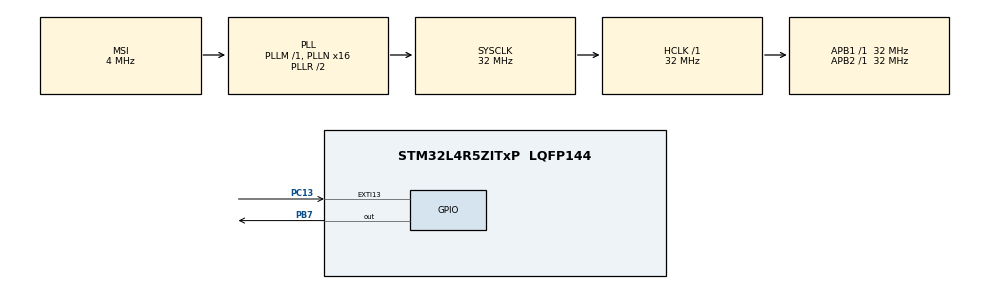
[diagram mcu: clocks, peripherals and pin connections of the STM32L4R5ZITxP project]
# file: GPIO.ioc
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Mcu.Family=STM32L4
Mcu.Name=STM32L4R5ZITxP
Mcu.Package=LQFP144
NVIC.EXTI15_10_IRQn=true\:0\:0\:false\:false\:true\:true\:true\:true
NVIC.PriorityGroup=NVIC_PRIORITYGROUP_4
PB7.Signal=GPIO_Output
PC13.Signal=GPXTI13
PC14-OSC32_IN\ (PC14).Mode=LSE-External-Oscillator
PC14-OSC32_IN\ (PC14).Signal=RCC_OSC32_IN
PC15-OSC32_OUT\ (PC15).Mode=LSE-External-Oscillator
PC15-OSC32_OUT\ (PC15).Signal=RCC_OSC32_OUT
PH0-OSC_IN\ (PH0).Mode=HSE-External-Oscillator
PH0-OSC_IN\ (PH0).Signal=RCC_OSC_IN
PH1-OSC_OUT\ (PH1).Mode=HSE-External-Oscillator
PH1-OSC_OUT\ (PH1).Signal=RCC_OSC_OUT
ProjectManager.HeapSize=0x200
ProjectManager.StackSize=0x400
ProjectManager.TargetToolchain=STM32CubeIDE
RCC.ADCFreq_Value=48000000
RCC.AHBFreq_Value=32000000
RCC.APB1Freq_Value=32000000
RCC.APB1TimFreq_Value=32000000
RCC.APB2Freq_Value=32000000
RCC.APB2TimFreq_Value=32000000
RCC.CortexFreq_Value=32000000
RCC.HCLKFreq_Value=32000000
RCC.HSE_VALUE=8000000
RCC.HSI48_VALUE=48000000
RCC.HSI_VALUE=16000000
RCC.MSI_VALUE=4000000
RCC.PLLN=16
RCC.PLLSAI1N=24
RCC.SYSCLKFreq_VALUE=32000000
RCC.SYSCLKSource=RCC_SYSCLKSOURCE_PLLCLK
RCC.USBFreq_Value=48000000
RCC.VCOOutputFreq_Value=64000000
board=NUCLEO-L4R5ZI-P

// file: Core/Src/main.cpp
/* USER CODE BEGIN Header */
/**
  ******************************************************************************
  * @file           : main.c
  * @brief          : Main program body
  ******************************************************************************
  * @attention
  *
  * Copyright (c) 2024 STMicroelectronics.
  * All rights reserved.
  *
  * This software is licensed under terms that can be found in the LICENSE file
  * in the root directory of this software component.
  * If no LICENSE file comes with this software, it is provided AS-IS.
  *
  ******************************************************************************
  */
/* USER CODE END Header */
#include "main.h"

/* USER CODE BEGIN Includes */
#include "Drivers/led_test.hpp"
/* USER CODE END Includes */

/* USER CODE BEGIN PD */
#define BUTTON_PIN GPIO_PIN_13
#define BUTTON_GPIO_PORT GPIOC
#define BUTTON_EXTI_IRQn EXTI15_10_IRQn

#define TIMER_INTERRUPT
//#define POOLING

// https://www.st.com/resource/en/reference_manual/rm0432-stm32l4-series-advanced-armbased-32bit-mcus-stmicroelectronics.pdf
// SYSCFG external interrupt configuration register 4
volatile uint32_t *SYSCFG_EXTICR4 = (uint32_t *)0x14;
// Rising trigger selection register 2 (EXTI_RTSR2)
volatile uint32_t *EXTI_RTSR2 = (uint32_t *)0x28;
// Falling trigger selection register 1 (EXTI_FTSR1)
volatile uint32_t *EXTI_FTSR1 = (uint32_t *)0x0C;

/* USER CODE END PD */

/* Private macro ----------------------------------s---------------------------*/
/* USER CODE BEGIN PM */
volatile bool buttonPressed = false; // Flag for button interrupt
/* USER CODE END PM */

void SystemClock_Config(void);
static void MX_GPIO_Init(void);

int main(void)
{

  /* MCU Configuration--------------------------------------------------------*/

  /* Reset of all peripherals, Initializes the Flash interface and the Systick. */
  HAL_Init();

  /* Configure the system clock */
  SystemClock_Config();

  /* Initialize all configured peripherals */
  MX_GPIO_Init();

  /* Infinite loop */
  /* USER CODE BEGIN WHILE */
  uint8_t led3Pin = GPIO_PIN_14;
  GPIO_TypeDef * led3Port = GPIOB;
  LED led3(led3Port, led3Pin);

  uint8_t led2Pin = GPIO_PIN_7;
  GPIO_TypeDef * led2Port = GPIOB;
  LED led2(led2Port, led2Pin);

  led3.turnLedOn();
  led2.turnLedOn();
  HAL_Delay(5000);
  led3.turnLedOff();
  led2.turnLedOff();
  HAL_Delay(5000);
  // This works without below configuration
  // set bits 7:4 to 0010 for PC13 pin
  *SYSCFG_EXTICR4 = 0x00008828;
  *EXTI_RTSR2 = 0x00000000;
  *EXTI_RTSR2 |= (0x1F << 3);   // Set bits 7:3 to 1 1111
//Example source :  https://deepbluembedded.com/stm32-external-interrupt-example-lab/

  while (1)
  {
#ifdef POOLING // This part works
	  if(HAL_GPIO_ReadPin(BUTTON_GPIO_PORT, BUTTON_PIN) == GPIO_PIN_SET)
	  {
		  HAL_Delay(50);
		  if(HAL_GPIO_ReadPin(BUTTON_GPIO_PORT, BUTTON_PIN) == GPIO_PIN_SET)
		  {
			  led2.turnLedOn();
		  }
		  else
		  {
			  led2.turnLedOff();
		  }
	  }
#endif
#ifdef TIMER_INTERRUPT
	  if (buttonPressed)
	  {
		  buttonPressed = false;
		  led2.turnLedOn();
		  HAL_Delay(1000); // Why we need this delay
	  }
	  else
	  {
		  led2.turnLedOff();
	  }
#endif
//	  led2.blinkLed();
//	  __NOP();

    /* USER CODE END WHILE */

  }
}

void SystemClock_Config(void)
{
  RCC_OscInitTypeDef RCC_OscInitStruct = {0};
  RCC_ClkInitTypeDef RCC_ClkInitStruct = {0};

  /** Configure the main internal regulator output voltage
  */
  if (HAL_PWREx_ControlVoltageScaling(PWR_REGULATOR_VOLTAGE_SCALE1) != HAL_OK)
  {
    Error_Handler();
  }

  /** Initializes the RCC Oscillators according to the specified parameters
  * in the RCC_OscInitTypeDef structure.
  */
  RCC_OscInitStruct.OscillatorType = RCC_OSCILLATORTYPE_MSI;
  RCC_OscInitStruct.MSIState = RCC_MSI_ON;
  RCC_OscInitStruct.MSICalibrationValue = 0;
  RCC_OscInitStruct.MSIClockRange = RCC_MSIRANGE_6;
  RCC_OscInitStruct.PLL.PLLState = RCC_PLL_ON;
  RCC_OscInitStruct.PLL.PLLSource = RCC_PLLSOURCE_MSI;
  RCC_OscInitStruct.PLL.PLLM = 1;
  RCC_OscInitStruct.PLL.PLLN = 16;
  RCC_OscInitStruct.PLL.PLLP = RCC_PLLP_DIV2;
  RCC_OscInitStruct.PLL.PLLQ = RCC_PLLQ_DIV2;
  RCC_OscInitStruct.PLL.PLLR = RCC_PLLR_DIV2;
  if (HAL_RCC_OscConfig(&RCC_OscInitStruct) != HAL_OK)
  {
    Error_Handler();
  }

  /** Initializes the CPU, AHB and APB buses clocks
  */
  RCC_ClkInitStruct.ClockType = RCC_CLOCKTYPE_HCLK|RCC_CLOCKTYPE_SYSCLK
                              |RCC_CLOCKTYPE_PCLK1|RCC_CLOCKTYPE_PCLK2;
  RCC_ClkInitStruct.SYSCLKSource = RCC_SYSCLKSOURCE_PLLCLK;
  RCC_ClkInitStruct.AHBCLKDivider = RCC_SYSCLK_DIV1;
  RCC_ClkInitStruct.APB1CLKDivider = RCC_HCLK_DIV1;
  RCC_ClkInitStruct.APB2CLKDivider = RCC_HCLK_DIV1;

  if (HAL_RCC_ClockConfig(&RCC_ClkInitStruct, FLASH_LATENCY_1) != HAL_OK)
  {
    Error_Handler();
  }
}

//static void MX_GPIO_Init(void)
//{
//  GPIO_InitTypeDef GPIO_InitStruct = {0};
///* USER CODE BEGIN MX_GPIO_Init_1 */
///* USER CODE END MX_GPIO_Init_1 */
//
//  /* GPIO Ports Clock Enable */
//  __HAL_RCC_GPIOC_CLK_ENABLE();
//  __HAL_RCC_GPIOH_CLK_ENABLE();
//  __HAL_RCC_GPIOB_CLK_ENABLE();
//
//  /*Configure GPIO pin Output Level */
//  HAL_GPIO_WritePin(GPIOB, GPIO_PIN_14|GPIO_PIN_7, GPIO_PIN_RESET);
//
//  /*Configure GPIO pins : PB14 PB7 */
//  GPIO_InitStruct.Pin = GPIO_PIN_14|GPIO_PIN_7;
//  GPIO_InitStruct.Mode = GPIO_MODE_OUTPUT_PP;
//  GPIO_InitStruct.Pull = GPIO_NOPULL;
//  GPIO_InitStruct.Speed = GPIO_SPEED_FREQ_LOW;
//  HAL_GPIO_Init(GPIOB, &GPIO_InitStruct);
//
///* USER CODE BEGIN MX_GPIO_Init_2 */
//  /*Configure GPIO pin : PC13 */
//    GPIO_InitStruct.Pin = GPIO_PIN_13;
//    GPIO_InitStruct.Mode = GPIO_MODE_IT_FALLING;
//    GPIO_InitStruct.Pull = GPIO_NOPULL;
//    HAL_GPIO_Init(GPIOC, &GPIO_InitStruct);
//
//#ifdef TIMER_INTERRUPT
//    // Enable and set EXTI line Interrupt to the lowest priority
//	HAL_NVIC_SetPriority(BUTTON_EXTI_IRQn, 2, 0);
//	HAL_NVIC_EnableIRQ(BUTTON_EXTI_IRQn);
//#endif
///* USER CODE END MX_GPIO_Init_2 */
//}

static void MX_GPIO_Init(void)
{
  GPIO_InitTypeDef GPIO_InitStruct = {0};

  /* GPIO Ports Clock Enable */
  __HAL_RCC_GPIOC_CLK_ENABLE();
  __HAL_RCC_GPIOH_CLK_ENABLE();
  __HAL_RCC_GPIOB_CLK_ENABLE();

  /*Configure GPIO pin Output Level */
  HAL_GPIO_WritePin(GPIOB, GPIO_PIN_7, GPIO_PIN_RESET);

  /*Configure GPIO pin : PC13 */
  GPIO_InitStruct.Pin = GPIO_PIN_13;
  GPIO_InitStruct.Mode = GPIO_MODE_IT_RISING;
  GPIO_InitStruct.Pull = GPIO_NOPULL;
  HAL_GPIO_Init(GPIOC, &GPIO_InitStruct);

  /*Configure GPIO pin : PB7 */
  GPIO_InitStruct.Pin = GPIO_PIN_7;
  GPIO_InitStruct.Mode = GPIO_MODE_OUTPUT_PP;
  GPIO_InitStruct.Pull = GPIO_NOPULL;
  GPIO_InitStruct.Speed = GPIO_SPEED_FREQ_LOW;
  HAL_GPIO_Init(GPIOB, &GPIO_InitStruct);
#ifdef TIMER_INTERRUPT
  /* EXTI interrupt init*/
  HAL_NVIC_SetPriority(EXTI15_10_IRQn, 0, 0);
  HAL_NVIC_EnableIRQ(EXTI15_10_IRQn);
#endif
}
/* USER CODE BEGIN 4 */
// Interrupt handler
// EXTI Line9 External Interrupt ISR Handler CallBackFun
void HAL_GPIO_EXTI_Callback(uint16_t GPIO_Pin)
{
    if(GPIO_Pin == GPIO_PIN_13) // If The INT Source Is EXTI Line9 (A9 Pin)
    {
    	buttonPressed = true;
    }
}
/* USER CODE END 4 */

void Error_Handler(void)
{
  __disable_irq();
  while (1)
  {
  }
}
